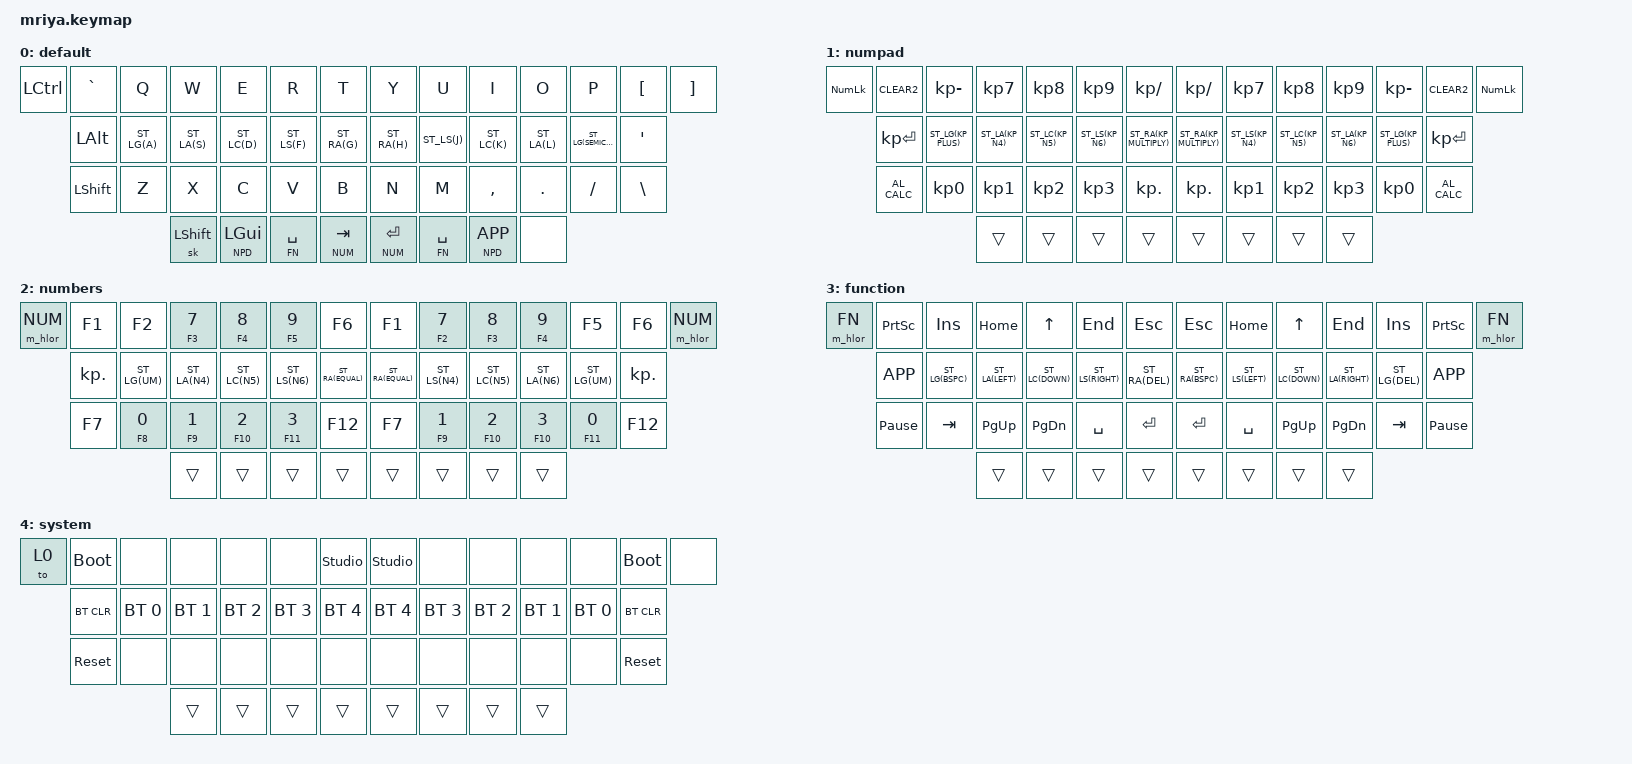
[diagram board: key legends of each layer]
/*
 * SPDX-License-Identifier: MIT
 */

#include <behaviors.dtsi>
#include <dt-bindings/zmk/bt.h>
#include <dt-bindings/zmk/keys.h>


#define DEF 0
#define NPD 1
#define NUM 2
#define FN  3
#define SYS 4


#define ST_LG(key) &hst_1000_225 LGUI key
#define ST_LA(key) &hst_1000_225 LALT key
#define ST_LC(key) &hst_1000_225 LCTRL key
#define ST_LS(key) &hst_1000_225 LSHIFT key
#define ST_RA(key) &hst_1000_225 RALT key


#define UM &mm_under_minus


&lt {
    quick-tap-ms = <200>;
    require-prior-idle-ms = <200>;
};

&mt {
    quick-tap-ms = <200>;
    require-prior-idle-ms = <200>;
};

/ {
    conditional_layers {
        compatible = "zmk,conditional-layers";

        tri_layer {
            if-layers = <1 2 3>;
            then-layer = <4>;
        };
    };

    macros {
        m_hlor: macro_hold_layer_on_release {
            compatible = "zmk,behavior-macro-one-param";
            #binding-cells = <1>;
            wait-ms = <40>;
            tap-ms = <40>;
            bindings =
                <&macro_pause_for_release>,
                <&macro_param_1to1>,
                <&macro_tap &to MACRO_PLACEHOLDER>;
        };
    };

    behaviors {
        sk_1000: sticky_key_1000 {
            compatible = "zmk,behavior-sticky-key";
            #binding-cells = <1>;
            bindings = <&kp>;
            release-after-ms = <1000>;
            quick-release;
            ignore-modifiers;
        };

        sk_1500: sticky_key_1500 {
            compatible = "zmk,behavior-sticky-key";
            #binding-cells = <1>;
            bindings = <&kp>;
            release-after-ms = <1500>;
            quick-release;
            ignore-modifiers;
        };

        hst_1000_225: hold_225_sticky_1000_tap {
            compatible = "zmk,behavior-hold-tap";
            #binding-cells = <2>;
            flavor = "balanced";
            tapping-term-ms = <225>;
            quick-tap-ms = <225>;
            // require-prior-idle-ms = <125>;
            bindings = <&sk_1000>, <&kp>;
        };

        mm_under_minus: reverse_under_minus {
            compatible = "zmk,behavior-mod-morph";
            #binding-cells = <0>;
            bindings = <&kp UNDER>, <&kp MINUS>;
            mods = <(MOD_LSFT | MOD_RSFT)>;
            keep-mods = <(MOD_LCTL | MOD_RCTL | MOD_LALT | MOD_RALT | MOD_LGUI | MOD_RGUI)>;
        };

        press_alt: press_alt {
            compatible = "zmk,behavior-mod-morph";
            #binding-cells = <0>;
            bindings = <&kt LALT>, <&none>;
            mods = <(MOD_LALT)>;
        };

        press_ctrl: press_ctrl {
            compatible = "zmk,behavior-mod-morph";
            #binding-cells = <0>;
            bindings = <&kt LCTRL>, <&none>;
            mods = <(MOD_LCTL)>;
        };

        press_shift: press_shift {
            compatible = "zmk,behavior-mod-morph";
            #binding-cells = <0>;
            bindings = <&kt LSHFT>, <&none>;
            mods = <(MOD_LSFT)>;
        };

        press_gui: press_gui {
            compatible = "zmk,behavior-mod-morph";
            #binding-cells = <0>;
            bindings = <&kt LGUI>, <&none>;
            mods = <(MOD_LGUI)>;
        };

        release_alt: release_alt {
            compatible = "zmk,behavior-mod-morph";
            #binding-cells = <0>;
            bindings = <&none>, <&kt LALT>;
            mods = <(MOD_LALT)>;
        };

        release_ralt: release_ralt {
            compatible = "zmk,behavior-mod-morph";
            #binding-cells = <0>;
            bindings = <&none>, <&kt RALT>;
            mods = <(MOD_RALT)>;
        };

        release_ctrl: release_ctrl {
            compatible = "zmk,behavior-mod-morph";
            #binding-cells = <0>;
            bindings = <&none>, <&kt LCTRL>;
            mods = <(MOD_LCTL)>;
        };

        release_shft: release_shft {
            compatible = "zmk,behavior-mod-morph";
            #binding-cells = <0>;
            bindings = <&none>, <&kt LSHFT>;
            mods = <(MOD_LSFT)>;
        };

        release_gui: release_gui {
            compatible = "zmk,behavior-mod-morph";
            #binding-cells = <0>;
            bindings = <&none>, <&kt LGUI>;
            mods = <(MOD_LGUI)>;
        };
    };

    keymap {
        compatible = "zmk,keymap";

        default {
            bindings = <
&kp LCTRL  &kp GRAVE  &kp Q     &kp W       &kp E         &kp R         &kp T          &kp Y          &kp U         &kp I          &kp O      &kp P             &kp LEFT_BRACKET  &kp RIGHT_BRACKET
           &kp LALT   ST_LG(A)  ST_LA(S)    ST_LC(D)      ST_LS(F)      ST_RA(G)       ST_RA(H)       ST_LS(J)      ST_LC(K)       ST_LA(L)   ST_LG(SEMICOLON)  &kp SQT
           &kp LSHFT  &kp Z     &kp X       &kp C         &kp V         &kp B          &kp N          &kp M         &kp COMMA      &kp DOT    &kp SLASH         &kp BSLH
                                &sk LSHFT   &lt NPD LGUI  &lt FN SPACE  &lt NUM TAB    &lt NUM ENTER  &lt FN SPACE  &lt NPD K_APP  &none
            >;
        };

        numpad {
            bindings = <
&kp KP_NUM  &kp CLEAR2     &kp KP_MINUS    &kp KP_N7     &kp KP_N8     &kp KP_N9     &kp KP_DIVIDE         &kp KP_DIVIDE       &kp KP_N7     &kp KP_N8     &kp KP_N9     &kp KP_MINUS    &kp CLEAR2     &kp KP_NUM
            &kp KP_ENTER   ST_LG(KP_PLUS)  ST_LA(KP_N4)  ST_LC(KP_N5)  ST_LS(KP_N6)  ST_RA(KP_MULTIPLY)    ST_RA(KP_MULTIPLY)  ST_LS(KP_N4)  ST_LC(KP_N5)  ST_LA(KP_N6)  ST_LG(KP_PLUS)  &kp KP_ENTER
            &kp C_AL_CALC  &kp KP_N0       &kp KP_N1     &kp KP_N2     &kp KP_N3     &kp KP_DOT            &kp KP_DOT          &kp KP_N1     &kp KP_N2     &kp KP_N3     &kp KP_N0       &kp C_AL_CALC
                                           &trans        &trans        &trans        &trans                &trans              &trans        &trans        &trans
            >;
        };

        numbers {
            bindings = <
&m_hlor NUM  &kp F1      &kp F2     &mt F3 N7  &mt F4 N8   &mt F5 N9   &kp F6          &kp F1        &mt F2 N7  &mt F3 N8   &mt F4 N9   &kp F5      &kp F6      &m_hlor NUM
             &kp KP_DOT  ST_LG(UM)  ST_LA(N4)  ST_LC(N5)   ST_LS(N6)   ST_RA(EQUAL)    ST_RA(EQUAL)  ST_LS(N4)  ST_LC(N5)   ST_LA(N6)   ST_LG(UM)   &kp KP_DOT
             &kp F7      &mt F8 N0  &mt F9 N1  &mt F10 N2  &mt F11 N3  &kp F12         &kp F7        &mt F9 N1  &mt F10 N2  &mt F10 N3  &mt F11 N0  &kp F12
                                    &trans     &trans      &trans      &trans          &trans        &trans     &trans      &trans
            >;
        };

        function {
            bindings = <
&m_hlor FN  &kp PSCRN        &kp INSERT   &kp HOME     &kp UP       &kp END       &kp ESC       &kp ESC      &kp HOME     &kp UP       &kp END       &kp INSERT  &kp PSCRN       &m_hlor FN
            &kp K_APP        ST_LG(BSPC)  ST_LA(LEFT)  ST_LC(DOWN)  ST_LS(RIGHT)  ST_RA(DEL)    ST_RA(BSPC)  ST_LS(LEFT)  ST_LC(DOWN)  ST_LA(RIGHT)  ST_LG(DEL)  &kp K_APP
            &kp PAUSE_BREAK  &kp TAB      &kp PG_UP    &kp PG_DN    &kp SPACE     &kp ENTER     &kp ENTER    &kp SPACE    &kp PG_UP    &kp PG_DN     &kp TAB     &kp PAUSE_BREAK
                                          &trans       &trans       &trans        &trans        &trans       &trans       &trans       &trans
            >;
        };

        system {
            bindings = <
&to 0  &bootloader  &none         &none         &none         &none         &studio_unlock    &studio_unlock  &none         &none         &none         &none         &bootloader  &none
       &bt BT_CLR   &bt BT_SEL 0  &bt BT_SEL 1  &bt BT_SEL 2  &bt BT_SEL 3  &bt BT_SEL 4      &bt BT_SEL 4    &bt BT_SEL 3  &bt BT_SEL 2  &bt BT_SEL 1  &bt BT_SEL 0  &bt BT_CLR
       &sys_reset   &none         &none         &none         &none         &none             &none           &none         &none         &none         &none         &sys_reset
                                  &trans        &trans        &trans        &trans            &trans          &trans        &trans        &trans
            >;
        };
    };
};
